AUTOSAR XML (schema 4-2-2)
package /Components
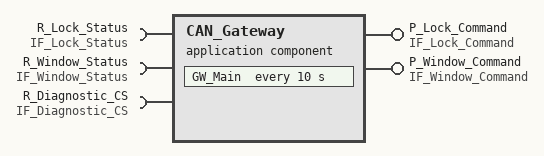
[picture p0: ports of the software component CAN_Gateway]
  application sw component type CAN_Gateway
    provide port P_Lock_Command: provided-interface=IF_Lock_Command
    provide port P_Window_Command: provided-interface=IF_Window_Command
    require port R_Lock_Status: required-interface=IF_Lock_Status
    require port R_Window_Status: required-interface=IF_Window_Status
    require port R_Diagnostic_CS: required-interface=IF_Diagnostic_CS
    behavior CAN_Gateway_InternalBehavior
      init event GW_Init_Event: start-on-event=GW_Main
      timing event GW_10ms_Event: start-on-event=GW_Main, period=10
      runnable GW_Main: minimum-start-interval=10
        data-receive-point-by-arguments:
          access VA_Read_LockStatus: accessed-variable=R_Lock_Status.lock_status
          access VA_Read_WindowStatus: accessed-variable=R_Window_Status.window_status
        data-send-points:
          access VA_Write_LockCmd: accessed-variable=P_Lock_Command.lock_cmd
          access VA_Write_WindowCmd: accessed-variable=P_Window_Command.window_cmd
        sync call SCP_Read_DID: operation=R_Diagnostic_CS.Read_DID, timeout=50
        sync call SCP_Clear_DTC: operation=R_Diagnostic_CS.Clear_DTC, timeout=50
        sync call SCP_Routine_Control: operation=R_Diagnostic_CS.Routine_Control, timeout=50
